# CTRL_MODULE_CORE register map
Vendor: Texas Instruments
Peripheral module from a debugger description file (folder DM50x).
Registers are 32-bit, access per field, reset 0x0 unless marked. A register's access mark holds for its fields unless they carry their own. Offsets are as the file gives them; lines under a group give offsets from that group; [hi:lo] are bit positions; {n}, {i} and the like mark numbered series; 'fields as' and 'values as' point back to an identical list; <NAME> marks a mode.

## CTRL_MODULE_CORE (part 1 of 5)
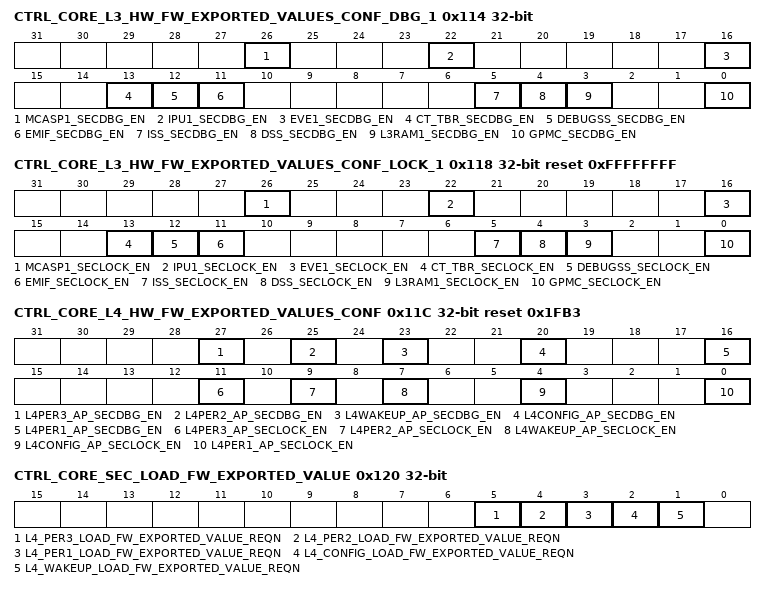
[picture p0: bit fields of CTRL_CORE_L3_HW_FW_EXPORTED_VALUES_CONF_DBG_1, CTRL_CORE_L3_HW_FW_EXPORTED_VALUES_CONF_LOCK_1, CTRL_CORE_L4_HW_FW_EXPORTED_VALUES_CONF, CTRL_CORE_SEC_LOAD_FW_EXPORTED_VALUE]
0x114 CTRL_CORE_L3_HW_FW_EXPORTED_VALUES_CONF_DBG_1
  [26] MCASP1_SECDBG_EN rw — Using a combination of x_SECDBG_EN and corresponding x_SECLOCK_EN bit from registerCTRL_CORE_L3_HW_FW_EXPORTED_VALUES_CONF_LOCK_1, different values can be exported to the corresponding L3 firewall. For more information, see , in .
  [22] IPU1_SECDBG_EN rw — Using a combination of x_SECDBG_EN and corresponding x_SECLOCK_EN bit from registerCTRL_CORE_L3_HW_FW_EXPORTED_VALUES_CONF_LOCK_1, different values can be exported to the corresponding L3 firewall. For more information, see , in .
  [16] EVE1_SECDBG_EN rw — Using a combination of x_SECDBG_EN and corresponding x_SECLOCK_EN bit from registerCTRL_CORE_L3_HW_FW_EXPORTED_VALUES_CONF_LOCK_1, different values can be exported to the corresponding L3 firewall. For more information, see , in .
  [13] CT_TBR_SECDBG_EN rw — Using a combination of x_SECDBG_EN and corresponding x_SECLOCK_EN bit from registerCTRL_CORE_L3_HW_FW_EXPORTED_VALUES_CONF_LOCK_1, different values can be exported to the corresponding L3 firewall. For more information, see , in .
  [12] DEBUGSS_SECDBG_EN rw — Using a combination of x_SECDBG_EN and corresponding x_SECLOCK_EN bit from registerCTRL_CORE_L3_HW_FW_EXPORTED_VALUES_CONF_LOCK_1, different values can be exported to the corresponding L3 firewall. For more information, see , in .
  [11] EMIF_SECDBG_EN rw — Using a combination of x_SECDBG_EN and corresponding x_SECLOCK_EN bit from registerCTRL_CORE_L3_HW_FW_EXPORTED_VALUES_CONF_LOCK_1, different values can be exported to the corresponding L3 firewall. For more information, see , in .
  [5] ISS_SECDBG_EN rw — Using a combination of x_SECDBG_EN and corresponding x_SECLOCK_EN bit from registerCTRL_CORE_L3_HW_FW_EXPORTED_VALUES_CONF_LOCK_1, different values can be exported to the corresponding L3 firewall. For more information, see , in .
  [4] DSS_SECDBG_EN rw — Using a combination of x_SECDBG_EN and corresponding x_SECLOCK_EN bit from registerCTRL_CORE_L3_HW_FW_EXPORTED_VALUES_CONF_LOCK_1, different values can be exported to the corresponding L3 firewall. For more information, see , in .
  [3] L3RAM1_SECDBG_EN rw — Using a combination of x_SECDBG_EN and corresponding x_SECLOCK_EN bit from registerCTRL_CORE_L3_HW_FW_EXPORTED_VALUES_CONF_LOCK_1, different values can be exported to the corresponding L3 firewall. For more information, see , in .
  [0] GPMC_SECDBG_EN rw — Using a combination of x_SECDBG_EN and corresponding x_SECLOCK_EN bit from registerCTRL_CORE_L3_HW_FW_EXPORTED_VALUES_CONF_LOCK_1, different values can be exported to the corresponding L3 firewall. For more information, see , in .
0x118 CTRL_CORE_L3_HW_FW_EXPORTED_VALUES_CONF_LOCK_1 reset 0xFFFFFFFF
  [26] MCASP1_SECLOCK_EN rw — Using a combination of x_SECLOCK_EN and corresponding x_SECDBG_EN bit from registerCTRL_CORE_L3_HW_FW_EXPORTED_VALUES_CONF_DBG_1, different values can be exported to the corresponding L3 firewall. For more information, see , in .
  [22] IPU1_SECLOCK_EN rw — Using a combination of x_SECLOCK_EN and corresponding x_SECDBG_EN bit from registerCTRL_CORE_L3_HW_FW_EXPORTED_VALUES_CONF_DBG_1, different values can be exported to the corresponding L3 firewall. For more information, see , in .
  [16] EVE1_SECLOCK_EN rw — Using a combination of x_SECLOCK_EN and corresponding x_SECDBG_EN bit from registerCTRL_CORE_L3_HW_FW_EXPORTED_VALUES_CONF_DBG_1, different values can be exported to the corresponding L3 firewall. For more information, see , in .
  [13] CT_TBR_SECLOCK_EN rw — Using a combination of x_SECLOCK_EN and corresponding x_SECDBG_EN bit from registerCTRL_CORE_L3_HW_FW_EXPORTED_VALUES_CONF_DBG_1, different values can be exported to the corresponding L3 firewall. For more information, see , in .
  [12] DEBUGSS_SECLOCK_EN rw — Using a combination of x_SECLOCK_EN and corresponding x_SECDBG_EN bit from registerCTRL_CORE_L3_HW_FW_EXPORTED_VALUES_CONF_DBG_1, different values can be exported to the corresponding L3 firewall. For more information, see , in .
  [11] EMIF_SECLOCK_EN rw — Using a combination of x_SECLOCK_EN and corresponding x_SECDBG_EN bit from registerCTRL_CORE_L3_HW_FW_EXPORTED_VALUES_CONF_DBG_1, different values can be exported to the corresponding L3 firewall. For more information, see , in .
  [5] ISS_SECLOCK_EN rw — Using a combination of x_SECLOCK_EN and corresponding x_SECDBG_EN bit from registerCTRL_CORE_L3_HW_FW_EXPORTED_VALUES_CONF_DBG_1, different values can be exported to the corresponding L3 firewall. For more information, see , in .
  [4] DSS_SECLOCK_EN rw — Using a combination of x_SECLOCK_EN and corresponding x_SECDBG_EN bit from registerCTRL_CORE_L3_HW_FW_EXPORTED_VALUES_CONF_DBG_1, different values can be exported to the corresponding L3 firewall. For more information, see , in .
  [3] L3RAM1_SECLOCK_EN rw — Using a combination of x_SECLOCK_EN and corresponding x_SECDBG_EN bit from registerCTRL_CORE_L3_HW_FW_EXPORTED_VALUES_CONF_DBG_1, different values can be exported to the corresponding L3 firewall. For more information, see , in .
  [0] GPMC_SECLOCK_EN rw — Using a combination of x_SECLOCK_EN and corresponding x_SECDBG_EN bit from registerCTRL_CORE_L3_HW_FW_EXPORTED_VALUES_CONF_DBG_1, different values can be exported to the corresponding L3 firewall. For more information, see , in .
0x11C CTRL_CORE_L4_HW_FW_EXPORTED_VALUES_CONF reset 0x1FB3
  [27] L4PER3_AP_SECDBG_EN rw — Using a combination of x_SECLOCK_EN and corresponding x_SECDBG_EN bit, different values can be exported to the corresponding L4 firewall. For more information, see table, in .
  [25] L4PER2_AP_SECDBG_EN rw — Using a combination of x_SECLOCK_EN and corresponding x_SECDBG_EN bit, different values can be exported to the corresponding L4 firewall. For more information, see table, in .
  [23] L4WAKEUP_AP_SECDBG_EN rw — Using a combination of x_SECLOCK_EN and corresponding x_SECDBG_EN bit, different values can be exported to the corresponding L4 firewall. For more information, see table, in .
  [20] L4CONFIG_AP_SECDBG_EN rw — Using a combination of x_SECLOCK_EN and corresponding x_SECDBG_EN bit, different values can be exported to the corresponding L4 firewall. For more information, see table, in .
  [16] L4PER1_AP_SECDBG_EN rw — Using a combination of x_SECLOCK_EN and corresponding x_SECDBG_EN bit, different values can be exported to the corresponding L4 firewall. For more information, see table, in .
  [11] L4PER3_AP_SECLOCK_EN rw — Using a combination of x_SECLOCK_EN and corresponding x_SECDBG_EN bit, different values can be exported to the corresponding L4 firewall. For more information, see table, in .
  [9] L4PER2_AP_SECLOCK_EN rw — Using a combination of x_SECLOCK_EN and corresponding x_SECDBG_EN bit, different values can be exported to the corresponding L4 firewall. For more information, see table, in .
  [7] L4WAKEUP_AP_SECLOCK_EN rw — Using a combination of x_SECLOCK_EN and corresponding x_SECDBG_EN bit, different values can be exported to the corresponding L4 firewall. For more information, see table, in .
  [4] L4CONFIG_AP_SECLOCK_EN rw — Using a combination of x_SECLOCK_EN and corresponding x_SECDBG_EN bit, different values can be exported to the corresponding L4 firewall. For more information, see table, in .
  [0] L4PER1_AP_SECLOCK_EN rw — Using a combination of x_SECLOCK_EN and corresponding x_SECDBG_EN bit, different values can be exported to the corresponding L4 firewall. For more information, see table, in .
0x120 CTRL_CORE_SEC_LOAD_FW_EXPORTED_VALUE
  [all] fields
    0=REQUESTED (LOAD FW exported values currently requested); 1=LOADED (FW exported values are LOADED)
  [5] L4_PER3_LOAD_FW_EXPORTED_VALUE_REQN rw — LOAD FW exported values.
  [4] L4_PER2_LOAD_FW_EXPORTED_VALUE_REQN rw — LOAD FW exported values.
  [3] L4_PER1_LOAD_FW_EXPORTED_VALUE_REQN rw — LOAD FW exported values.
  [2] L4_CONFIG_LOAD_FW_EXPORTED_VALUE_REQN rw — LOAD FW exported values.
  [1] L4_WAKEUP_LOAD_FW_EXPORTED_VALUE_REQN rw — LOAD FW exported values.
0x134 CTRL_CORE_STATUS ro reset 0xC0 — Control Module Status Register
  [8:6] DEVICE_TYPE — Device type captured at reset time. Read 0x3 = General Purpose (GP)
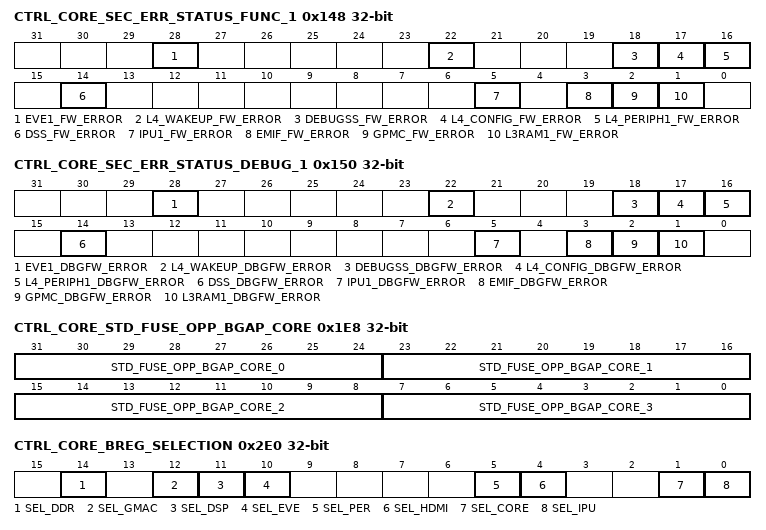
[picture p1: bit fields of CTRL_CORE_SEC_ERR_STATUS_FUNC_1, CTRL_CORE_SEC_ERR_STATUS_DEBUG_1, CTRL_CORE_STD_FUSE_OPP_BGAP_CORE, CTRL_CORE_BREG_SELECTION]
0x148 CTRL_CORE_SEC_ERR_STATUS_FUNC_1 access not given — Firewall Error Status functional Register 1
  [28] EVE1_FW_ERROR — EVE1 firewall 0x0 = No error from firewall 0x1 = Error from firewall (access RW W1toClr)
  [22] L4_WAKEUP_FW_ERROR — L4 wakeup firewall 0x0 = No error from firewall 0x1 = Error from firewall (access RW W1toClr)
  [18] DEBUGSS_FW_ERROR — DebugSS firewall 0x0 = No error from firewall 0x1 = Error from firewall (access RW W1toClr)
  [17] L4_CONFIG_FW_ERROR — L4 config firewall 0x0 = No error from firewall 0x1 = Error from firewall (access RW W1toClr)
  [16] L4_PERIPH1_FW_ERROR — L4 periph1 firewall 0x0 = No error from firewall 0x1 = Error from firewall (access RW W1toClr)
  [14] DSS_FW_ERROR — DSS firewall 0x0 = No error from firewall 0x1 = Error from firewall (access RW W1toClr)
  [5] IPU1_FW_ERROR — IPU1 firewall 0x0 = No error from firewall 0x1 = Error from firewall (access RW W1toClr)
  [3] EMIF_FW_ERROR — EMIF firewall 0x0 = No error from firewall 0x1 = Error from firewall (access RW W1toClr)
  [2] GPMC_FW_ERROR — GPMC firewall 0x0 = No error from firewall 0x1 = Error from firewall (access RW W1toClr)
  [1] L3RAM1_FW_ERROR — L3RAM1 firewall 0x0 = No error from firewall 0x1 = Error from firewall (access RW W1toClr)
0x150 CTRL_CORE_SEC_ERR_STATUS_DEBUG_1 access not given — Firewall Error Status Debug Register 1
  [28] EVE1_DBGFW_ERROR — EVE1 firewall 0x0 = No error from firewall 0x1 = Error from firewall (access RW W1toClr)
  [22] L4_WAKEUP_DBGFW_ERROR — L4 wakeup firewall 0x0 = No error from firewall 0x1 = Error from firewall (access RW W1toClr)
  [18] DEBUGSS_DBGFW_ERROR — DebugSS firewall 0x0 = No error from firewall 0x1 = Error from firewall (access RW W1toClr)
  [17] L4_CONFIG_DBGFW_ERROR — L4 config firewall 0x0 = No error from firewall 0x1 = Error from firewall (access RW W1toClr)
  [16] L4_PERIPH1_DBGFW_ERROR — L4 periph1 firewall 0x0 = No error from firewall 0x1 = Error from firewall (access RW W1toClr)
  [14] DSS_DBGFW_ERROR — DSS debug firewall 0x0 = No error from firewall 0x1 = Error from firewall (access RW W1toClr)
  [5] IPU1_DBGFW_ERROR — IPU1 debug firewall 0x0 = No error from firewall 0x1 = Error from firewall (access RW W1toClr)
  [3] EMIF_DBGFW_ERROR — EMIF debug firewall 0x0 = No error from firewall 0x1 = Error from firewall (access RW W1toClr)
  [2] GPMC_DBGFW_ERROR — GPMC debug firewall 0x0 = No error from firewall 0x1 = Error from firewall (access RW W1toClr)
  [1] L3RAM1_DBGFW_ERROR — L3RAM1 debug firewall 0x0 = No error from firewall 0x1 = Error from firewall (access RW W1toClr)
{0x1CC+4i} CTRL_CORE_STD_FUSE_OPP_VDD_CORE_{i} ro (i=0..4) — Standard Fuse OPP VDD_CORE [{32i+31}:{32i}]. Register shows part of the chip eFuse configuration on the OCP interface. Reading at the address of one of these registers provides a direct view into a part of the eFuse chain.
  [31:0] STD_FUSE_OPP_VDD_CORE_{i}
0x1E8 CTRL_CORE_STD_FUSE_OPP_BGAP_CORE ro reset not defined — Trim values for CORE associated temperature sensor and bandgap. Contains TI Internal information, not intended for application use.
  [31-8n:24-8n] STD_FUSE_OPP_BGAP_CORE_{n} (n=0..3) — Trim values for CORE associated temperature sensor and bandgap. Contains TI Internal information, not intended for application use.
{0x220+4i} CTRL_CORE_STD_FUSE_MPK_{i} ro (i=0..7) — Standard Fuse keys. Root_public_key_hash [{32i+31}:{32i}]. Register shows part of the chip eFuse configuration on the OCP interface. Reading at the address of one of these registers provides a direct view into a part of the eFuse chain.
  [31:0] STD_FUSE_MPK_{i}
0x2BC CTRL_CORE_CUST_FUSE_SWRV_0 ro — Customer Fuse keys. Software Version Control [031:000] (16 bits upper Redundant field) [FIELD OVERFLOW]. Register shows part of the chip eFuse configuration on the OCP interface. Reading at the address of one of these registers provides a direct view into a part of the eFuse chain.
  [31:0] CUST_FUSE_SWRV_0
0x2C0 CTRL_CORE_CUST_FUSE_SWRV_1 ro — Customer Fuse keys. Software Version Control [063:032] (16 bits upper Redundant field) [FIELD F]. Register shows part of the chip eFuse configuration on the OCP interface. Reading at the address of one of these registers provides a direct view into a part of the eFuse chain.
  [31:0] CUST_FUSE_SWRV_1
0x2C4 CTRL_CORE_CUST_FUSE_SWRV_2 ro — Customer Fuse keys. Software Version Control [095:064] (16 bits upper Redundant field) [FIELD E]. Register shows part of the chip eFuse configuration on the OCP interface. Reading at the address of one of these registers provides a direct view into a part of the eFuse chain.
  [31:0] CUST_FUSE_SWRV_2
0x2C8 CTRL_CORE_CUST_FUSE_SWRV_3 ro — Customer Fuse keys. Software Version Control [127:096] (16 bits upper Redundant field) [FIELD D]. Register shows part of the chip eFuse configuration on the OCP interface. Reading at the address of one of these registers provides a direct view into a part of the eFuse chain.
  [31:0] CUST_FUSE_SWRV_3
0x2CC CTRL_CORE_CUST_FUSE_SWRV_4 ro — Customer Fuse keys. Software Version Control [159:127] (16 bits upper Redundant field) [FIELD C]. Register shows part of the chip eFuse configuration on the OCP interface. Reading at the address of one of these registers provides a direct view into a part of the eFuse chain.
  [31:0] CUST_FUSE_SWRV_4
0x2D0 CTRL_CORE_CUST_FUSE_SWRV_5 ro — Customer Fuse keys. Software Version Control [191:160] (16 bits upper Redundant field) [FIELD B]. Register shows part of the chip eFuse configuration on the OCP interface. Reading at the address of one of these registers provides a direct view into a part of the eFuse chain.
  [31:0] CUST_FUSE_SWRV_5
0x2D4 CTRL_CORE_CUST_FUSE_SWRV_6 ro — Customer Fuse keys. Software Version Control [223:192] (16 bits upper Redundant field) [FIELD A]. Register shows part of the chip eFuse configuration on the OCP interface. Reading at the address of one of these registers provides a direct view into a part of the eFuse chain.
  [31:0] CUST_FUSE_SWRV_6
0x2E0 CTRL_CORE_BREG_SELECTION — DPLL selection
  [14] SEL_DDR rw — Selection ddr 0x0 = no dpll selected 0x1 = rdpll selected
  [12] SEL_GMAC rw — Selection gmac 0x0 = no dpll selected 0x1 = rdpll selected
  [11] SEL_DSP rw — Selection dsp 0x0 = no dpll selected 0x1 = rdpll selected
  [10] SEL_EVE rw — Selection eve 0x0 = no dpll selected 0x1 = rdpll selected
  [5] SEL_PER rw — Selection per 0x0 = no dpll selected 0x1 = rdpll selected
  [4] SEL_HDMI rw — Selection hdmi 0x0 = no dpll selected 0x1 = rdpll selected
  [1] SEL_CORE rw — Selection core 0x0 = no dpll selected 0x1 = rdpll selected
  [0] SEL_IPU rw — Selection ipu 0x0 = no dpll selected 0x1 = rdpll selected
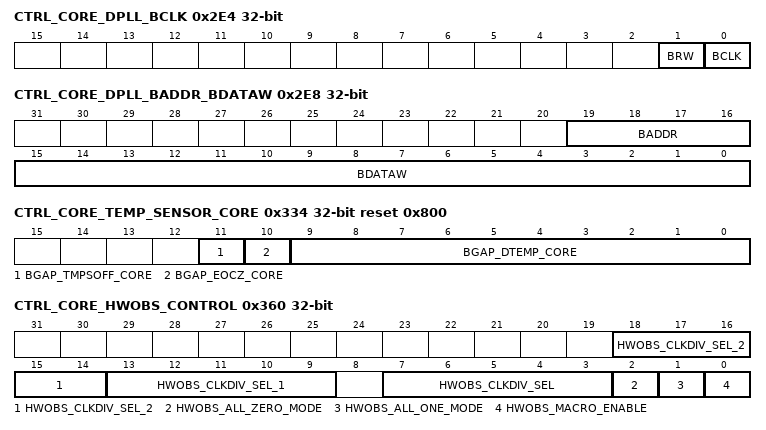
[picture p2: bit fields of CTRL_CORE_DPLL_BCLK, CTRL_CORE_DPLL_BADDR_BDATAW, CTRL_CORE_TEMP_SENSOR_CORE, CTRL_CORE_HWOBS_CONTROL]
0x2E4 CTRL_CORE_DPLL_BCLK — DPPL obs
  [1] BRW rw — Reset 0x0 = no reset 0x1 = reset
  [0] BCLK rw — clock
0x2E8 CTRL_CORE_DPLL_BADDR_BDATAW — DPLL addr and dataw
  [19:16] BADDR rw, [15:0] BDATAW rw
0x2EC CTRL_CORE_DPLL_BDATAR ro — DPLL datar
  [15:0] BDATAR — datar
0x334 CTRL_CORE_TEMP_SENSOR_CORE ro reset 0x800 — Control VBGAPTS temperature sensor and thermal comparator shutdown register
  [11] BGAP_TMPSOFF_CORE — This bit indicates the temperature sensor state.
  [10] BGAP_EOCZ_CORE — ADC End of Conversion. Active low, when BGAP_DTEMP_CORE is valid.
  [9:0] BGAP_DTEMP_CORE — Temperature data from the ADC. Valid if EOCZ is low.
0x358 CTRL_CORE_CORTEX_M4_MMUADDRTRANSLTR — Cortex M4 register
  [19:0] CORTEX_M4_MMUADDRTRANSLTR rw — Used to save the mmu address boot
0x35C CTRL_CORE_CORTEX_M4_MMUADDRLOGICTR
  [19:0] CORTEX_M4_MMUADDRLOGICTR rw
0x360 CTRL_CORE_HWOBS_CONTROL — HW observability control. This register enables or disables HW observability outputs (to save power primarily)
  [18:14] HWOBS_CLKDIV_SEL_2 rw — Clock divider selection for obs2 line. 0x1 = output is not divided 0x2 = output is divided by 2 0x4 = output is divided by 4 0x8 = output is divided by 8 0x10 = output is divided by 16
  [13:9] HWOBS_CLKDIV_SEL_1 rw — Clock divider selection for obs1 line. 0x1 = output is not divided 0x2 = output is divided by 2 0x4 = output is divided by 4 0x8 = output is divided by 8 0x10 = output is divided by 16
  [7:3] HWOBS_CLKDIV_SEL rw — Clock divider selection for obs0 line. 0x1 = output is not divided 0x2 = output is divided by 2 0x4 = output is divided by 4 0x8 = output is divided by 8 0x10 = output is divided by 16
  [2] HWOBS_ALL_ZERO_MODE rw — Used to gate observable signals. When set all outputs are set to zero (can be used to check the path from HW observability to external pads). 0x0 = hw observability ports are not gated 0x1 = hw observability ports are all set to 0
  [1] HWOBS_ALL_ONE_MODE rw — Used to gate observable signals. When set all outputs are set to one (can be used to check the path from HW observability to external pads). 0x0 = hw observability ports are not gated 0x1 = hw observability ports are all set to 1
  [0] HWOBS_MACRO_ENABLE rw — Used to gate observable signals coming from macros using the 32-bit HWOBS bus definition. When deasserted all outputs of the HWOBS busdef are set to zero. 0x0 = hw observability ports from macros are gated and set to zero 0x1 = hw observability ports from macros are not gated
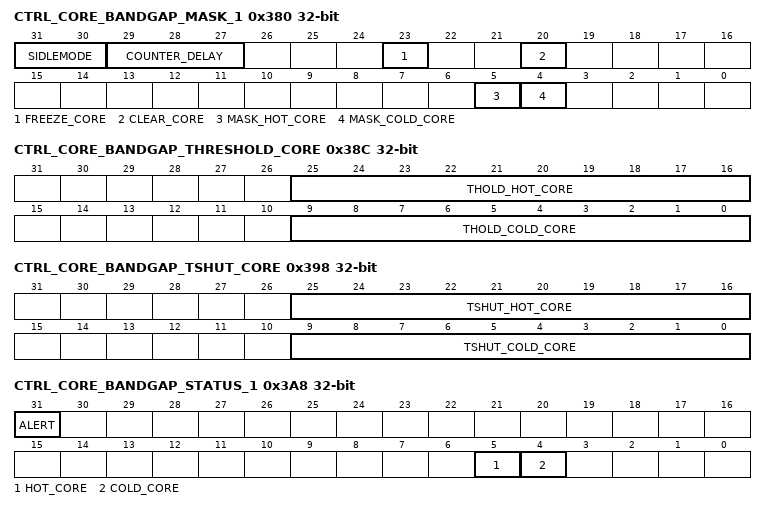
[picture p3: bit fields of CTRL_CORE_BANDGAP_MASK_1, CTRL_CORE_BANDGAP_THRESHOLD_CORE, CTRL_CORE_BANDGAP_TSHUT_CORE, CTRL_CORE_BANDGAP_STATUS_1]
0x380 CTRL_CORE_BANDGAP_MASK_1 — bgap_mask
  [31:30] SIDLEMODE rw — sidlemode for bandgap 0x0 = No Idle 0x1 = Force Idle 0x2 = Smart Idle 0x3 = Reserved
  [29:27] COUNTER_DELAY rw — Counter delay 0x0 = Imediat 0x1 = Delay of 1ms 0x2 = Delay of 10ms 0x3 = Delay of 100ms 0x4 = Delay of 250ms 0x5 = Delay of 500ms
  [23] FREEZE_CORE rw — Freeze the FIFO CORE 0x0 = No operation 0x1 = Freeze the FIFO
  [20] CLEAR_CORE rw — Reset the FIFO CORE 0x0 = No operation 0x1 = Reset the FIFO
  [5] MASK_HOT_CORE rw — Mask for hot event CORE 0x0 = hot event is masked 0x1 = hot event is not masked
  [4] MASK_COLD_CORE rw — Mask for cold event CORE 0x0 = cold event is masked 0x1 = cold event is not masked
0x38C CTRL_CORE_BANDGAP_THRESHOLD_CORE — BGAP THRESHOLD CORE
  [25:16] THOLD_HOT_CORE rw — Value for the high temperature threshold. The values for loading this bit field are listed in.
  [9:0] THOLD_COLD_CORE rw — Value for the low temperature threshold. The values for loading this bit field are listed in.
0x398 CTRL_CORE_BANDGAP_TSHUT_CORE ro — BGAP TSHUT THRESHOLD CORE
  [25:16] TSHUT_HOT_CORE — tshut value hot
  [9:0] TSHUT_COLD_CORE — tshut value cold
0x3A8 CTRL_CORE_BANDGAP_STATUS_1 ro — BGAP STATUS
  [31] ALERT — Alert temperature when '1'
  [5] HOT_CORE — Event for hot temperature mpu bandgap when '1' 0x0 = event not detected 0x1 = event detected
  [4] COLD_CORE — Event for cold temperature mpu bandgap when '1' 0x0 = event not detected 0x1 = event detected
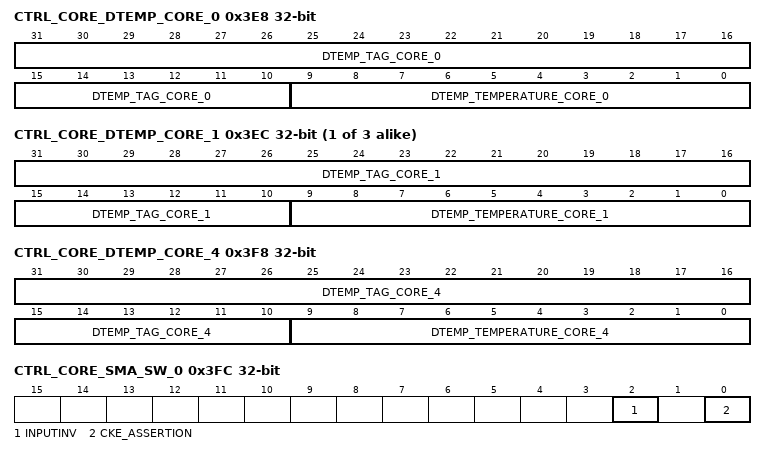
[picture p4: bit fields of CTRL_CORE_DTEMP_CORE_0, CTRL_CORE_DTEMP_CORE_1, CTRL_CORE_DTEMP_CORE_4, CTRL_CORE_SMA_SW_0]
0x3E8 CTRL_CORE_DTEMP_CORE_0 ro — TAGGED TEMPERATURE CORE DOMAIN. Most recent sample.
  [31:10] DTEMP_TAG_CORE_0 — tag. Indicate number of times in the bgap state machine.
  [9:0] DTEMP_TEMPERATURE_CORE_0 — temperature
{0x3E8+4i} CTRL_CORE_DTEMP_CORE_{i} ro (i=1..3) — TAGGED TEMPERATURE CORE DOMAIN
  [31:10] DTEMP_TAG_CORE_{i} — tag. Indicate number of times in the bgap state machine.
  [9:0] DTEMP_TEMPERATURE_CORE_{i} — temperature
0x3F8 CTRL_CORE_DTEMP_CORE_4 ro — TAGGED TEMPERATURE CORE DOMAIN. Oldest sample.
  [31:10] DTEMP_TAG_CORE_4 — tag. Indicate number of times in the bgap state machine.
  [9:0] DTEMP_TEMPERATURE_CORE_4 — temperature
0x3FC CTRL_CORE_SMA_SW_0 — Inversion control for SD_DAC input data – DIN[9:0].
  [2] INPUTINV rw — Inversion control for SD_DAC input data – DIN[9:0]. Allows polarity alignment with VENC data. 0x0: This value should be used for inverted video input data 0x1: This value should be used for non-inverted video input data
  [0] CKE_ASSERTION rw — Forces the EMIF CKE pad to tri-state. 0x0: The CKE pad is not in tri-state and can be controlled by EMIF 0x1: The CKE pad is in tri-state
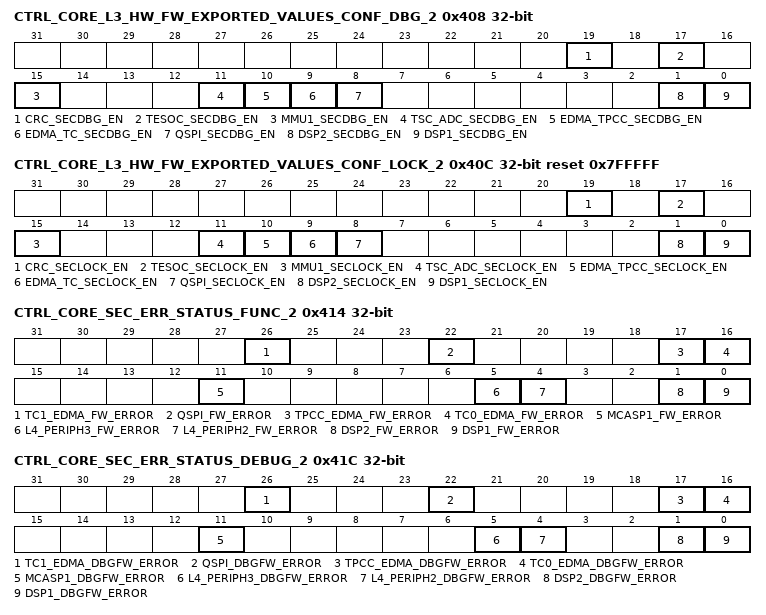
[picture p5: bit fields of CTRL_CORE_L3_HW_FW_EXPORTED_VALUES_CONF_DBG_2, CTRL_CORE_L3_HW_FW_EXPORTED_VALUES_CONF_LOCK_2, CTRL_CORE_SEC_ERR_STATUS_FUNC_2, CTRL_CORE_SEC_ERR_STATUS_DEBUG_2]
0x408 CTRL_CORE_L3_HW_FW_EXPORTED_VALUES_CONF_DBG_2
  [19] CRC_SECDBG_EN rw — Using a combination of x_SECDBG_EN and corresponding x_SECLOCK_EN bit from registerCTRL_CORE_L3_HW_FW_EXPORTED_VALUES_CONF_LOCK_2, different values can be exported to the corresponding L3 firewall. For more information, see , in .
  [17] TESOC_SECDBG_EN rw — Using a combination of x_SECDBG_EN and corresponding x_SECLOCK_EN bit from registerCTRL_CORE_L3_HW_FW_EXPORTED_VALUES_CONF_LOCK_2, different values can be exported to the corresponding L3 firewall. For more information, see , in .
  [15] MMU1_SECDBG_EN rw — Using a combination of x_SECDBG_EN and corresponding x_SECLOCK_EN bit from registerCTRL_CORE_L3_HW_FW_EXPORTED_VALUES_CONF_LOCK_2, different values can be exported to the corresponding L3 firewall. For more information, see , in .
  [11] TSC_ADC_SECDBG_EN rw — Using a combination of x_SECDBG_EN and corresponding x_SECLOCK_EN bit from registerCTRL_CORE_L3_HW_FW_EXPORTED_VALUES_CONF_LOCK_2, different values can be exported to the corresponding L3 firewall. For more information, see , in .
  [10] EDMA_TPCC_SECDBG_EN rw — Using a combination of x_SECDBG_EN and corresponding x_SECLOCK_EN bit from registerCTRL_CORE_L3_HW_FW_EXPORTED_VALUES_CONF_LOCK_2, different values can be exported to the corresponding L3 firewall. For more information, see , in .
  [9] EDMA_TC_SECDBG_EN rw — Using a combination of x_SECDBG_EN and corresponding x_SECLOCK_EN bit from registerCTRL_CORE_L3_HW_FW_EXPORTED_VALUES_CONF_LOCK_2, different values can be exported to the corresponding L3 firewall. For more information, see , in .
  [8] QSPI_SECDBG_EN rw — Using a combination of x_SECDBG_EN and corresponding x_SECLOCK_EN bit from registerCTRL_CORE_L3_HW_FW_EXPORTED_VALUES_CONF_LOCK_2, different values can be exported to the corresponding L3 firewall. For more information, see , in .
  [1] DSP2_SECDBG_EN rw — Using a combination of x_SECDBG_EN and corresponding x_SECLOCK_EN bit from registerCTRL_CORE_L3_HW_FW_EXPORTED_VALUES_CONF_LOCK_2, different values can be exported to the corresponding L3 firewall. For more information, see , in .
  [0] DSP1_SECDBG_EN rw — Using a combination of x_SECDBG_EN and corresponding x_SECLOCK_EN bit from registerCTRL_CORE_L3_HW_FW_EXPORTED_VALUES_CONF_LOCK_2, different values can be exported to the corresponding L3 firewall. For more information, see , in .
0x40C CTRL_CORE_L3_HW_FW_EXPORTED_VALUES_CONF_LOCK_2 reset 0x7FFFFF
  [19] CRC_SECLOCK_EN rw — Using a combination of x_SECLOCK_EN and corresponding x_SECDBG_EN bit from registerCTRL_CORE_L3_HW_FW_EXPORTED_VALUES_CONF_DBG_2, different values can be exported to the corresponding L3 firewall. For more information, see , in .
  [17] TESOC_SECLOCK_EN rw — Using a combination of x_SECLOCK_EN and corresponding x_SECDBG_EN bit from registerCTRL_CORE_L3_HW_FW_EXPORTED_VALUES_CONF_DBG_2, different values can be exported to the corresponding L3 firewall. For more information, see , in .
  [15] MMU1_SECLOCK_EN rw — Using a combination of x_SECLOCK_EN and corresponding x_SECDBG_EN bit from registerCTRL_CORE_L3_HW_FW_EXPORTED_VALUES_CONF_DBG_2, different values can be exported to the corresponding L3 firewall. For more information, see , in .
  [11] TSC_ADC_SECLOCK_EN rw — Using a combination of x_SECLOCK_EN and corresponding x_SECDBG_EN bit from registerCTRL_CORE_L3_HW_FW_EXPORTED_VALUES_CONF_DBG_2, different values can be exported to the corresponding L3 firewall. For more information, see , in .
  [10] EDMA_TPCC_SECLOCK_EN rw — Using a combination of x_SECLOCK_EN and corresponding x_SECDBG_EN bit from registerCTRL_CORE_L3_HW_FW_EXPORTED_VALUES_CONF_DBG_2, different values can be exported to the corresponding L3 firewall. For more information, see , in .
  [9] EDMA_TC_SECLOCK_EN rw — Using a combination of x_SECLOCK_EN and corresponding x_SECDBG_EN bit from registerCTRL_CORE_L3_HW_FW_EXPORTED_VALUES_CONF_DBG_2, different values can be exported to the corresponding L3 firewall. For more information, see , in .
  [8] QSPI_SECLOCK_EN rw — Using a combination of x_SECLOCK_EN and corresponding x_SECDBG_EN bit from registerCTRL_CORE_L3_HW_FW_EXPORTED_VALUES_CONF_DBG_2, different values can be exported to the corresponding L3 firewall. For more information, see , in .
  [1] DSP2_SECLOCK_EN rw — Using a combination of x_SECLOCK_EN and corresponding x_SECDBG_EN bit from registerCTRL_CORE_L3_HW_FW_EXPORTED_VALUES_CONF_DBG_2, different values can be exported to the corresponding L3 firewall. For more information, see , in .
  [0] DSP1_SECLOCK_EN rw — Using a combination of x_SECLOCK_EN and corresponding x_SECDBG_EN bit from registerCTRL_CORE_L3_HW_FW_EXPORTED_VALUES_CONF_DBG_2, different values can be exported to the corresponding L3 firewall. For more information, see , in .
0x414 CTRL_CORE_SEC_ERR_STATUS_FUNC_2 access not given — Firewall Error Status functional Register 2
  [26] TC1_EDMA_FW_ERROR — EDMA TC1 firewall 0x0 = No error from firewall 0x1 = Error from firewall (access RW W1toClr)
  [22] QSPI_FW_ERROR — QSPI firewall 0x0 = No error from firewall 0x1 = Error from firewall (access RW W1toClr)
  [17] TPCC_EDMA_FW_ERROR — EDMA TPCC firewall 0x0 = No error from firewall 0x1 = Error from firewall (access RW W1toClr)
  [16] TC0_EDMA_FW_ERROR — EDMA TC0 firewall 0x0 = No error from firewall 0x1 = Error from firewall (access RW W1toClr)
  [11] MCASP1_FW_ERROR — McASP1 firewall 0x0 = No error from firewall 0x1 = Error from firewall (access RW W1toClr)
  [5] L4_PERIPH3_FW_ERROR — L4 periph3 init firewall 0x0 = No error from firewall 0x1 = Error from firewall (access RW W1toClr)
  [4] L4_PERIPH2_FW_ERROR — L4 periph2 init firewall 0x0 = No error from firewall 0x1 = Error from firewall (access RW W1toClr)
  [1] DSP2_FW_ERROR — DSP2 firewall 0x0 = No error from firewall 0x1 = Error from firewall (access RW W1toClr)
  [0] DSP1_FW_ERROR — DSP1 firewall 0x0 = No error from firewall 0x1 = Error from firewall (access RW W1toClr)
0x41C CTRL_CORE_SEC_ERR_STATUS_DEBUG_2 access not given — Firewall Error Status debug Register 2
  [26] TC1_EDMA_DBGFW_ERROR — EDMA TC1 debug firewall 0x0 = No error from firewall 0x1 = Error from firewall (access RW W1toClr)
  [22] QSPI_DBGFW_ERROR — QSPI debug firewall 0x0 = No error from firewall 0x1 = Error from firewall (access RW W1toClr)
  [17] TPCC_EDMA_DBGFW_ERROR — EDMA TPCC debug firewall 0x0 = No error from firewall 0x1 = Error from firewall (access RW W1toClr)
  [16] TC0_EDMA_DBGFW_ERROR — EDMA TC0 debug firewall 0x0 = No error from firewall 0x1 = Error from firewall (access RW W1toClr)
  [11] MCASP1_DBGFW_ERROR — McASP1 debug firewall 0x0 = No error from firewall 0x1 = Error from firewall (access RW W1toClr)
  [5] L4_PERIPH3_DBGFW_ERROR — L4 periph3 init firewall 0x0 = No error from firewall 0x1 = Error from firewall (access RW W1toClr)
  [4] L4_PERIPH2_DBGFW_ERROR — L4 periph2 init firewall 0x0 = No error from firewall 0x1 = Error from firewall (access RW W1toClr)
  [1] DSP2_DBGFW_ERROR — DSP2 firewall 0x0 = No error from firewall 0x1 = Error from firewall (access RW W1toClr)
  [0] DSP1_DBGFW_ERROR — DSP1 firewall 0x0 = No error from firewall 0x1 = Error from firewall (access RW W1toClr)
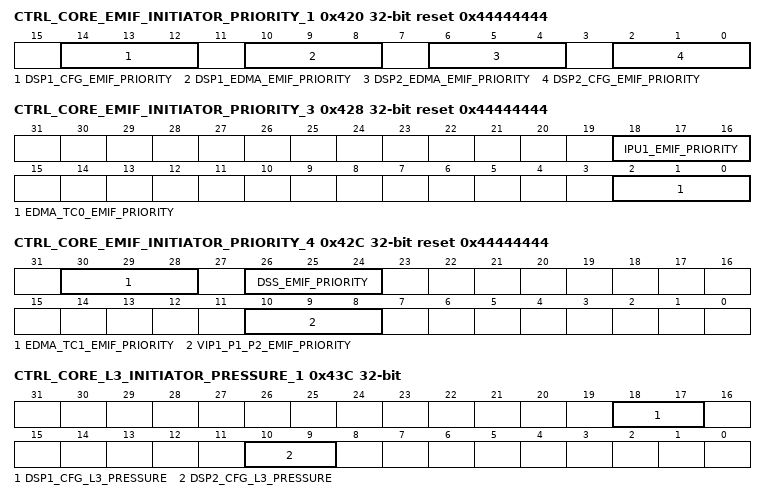
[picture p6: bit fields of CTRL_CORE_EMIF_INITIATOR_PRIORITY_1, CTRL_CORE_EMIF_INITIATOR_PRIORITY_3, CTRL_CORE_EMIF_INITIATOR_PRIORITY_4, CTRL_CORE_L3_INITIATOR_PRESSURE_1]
0x420 CTRL_CORE_EMIF_INITIATOR_PRIORITY_1 reset 0x44444444 — Register for priority settings for EMIF arbitration
  [14:12] DSP1_CFG_EMIF_PRIORITY rw — DSP1 CFG priority setting 0x0 = highest priority 0x7 = lowest priority
  [10:8] DSP1_EDMA_EMIF_PRIORITY rw — DSP1 EDMA priority setting 0x0 = highest priority 0x7 = lowest priority
  [6:4] DSP2_EDMA_EMIF_PRIORITY rw — DSP2 EDMA priority setting 0x0 = highest priority 0x7 = lowest priority
  [2:0] DSP2_CFG_EMIF_PRIORITY rw — DSP2 CFG priority setting 0x0 = highest priority 0x7 = lowest priority
0x424 CTRL_CORE_EMIF_INITIATOR_PRIORITY_2 reset 0x44044444 — Register for priority settings for EMIF arbitration
  [18:16] EVE1_TC0_EMIF_PRIORITY rw — EVE1 TC0 priority setting 0x0 = highest priority 0x7 = lowest priority
0x428 CTRL_CORE_EMIF_INITIATOR_PRIORITY_3 reset 0x44444444 — Register for priority settings for EMIF arbitration
  [18:16] IPU1_EMIF_PRIORITY rw — IPU1 priority setting 0x0 = highest prioroty 0x7 = lowest priority
  [2:0] EDMA_TC0_EMIF_PRIORITY rw — EDMA TC0 priority setting 0x0 = highest priority 0x7 = lowest priority
0x42C CTRL_CORE_EMIF_INITIATOR_PRIORITY_4 reset 0x44444444 — Register for priority settings for EMIF arbitration
  [30:28] EDMA_TC1_EMIF_PRIORITY rw — EDMA TC1 priority setting 0x0 = highest priority 0x7 = lowest priority
  [26:24] DSS_EMIF_PRIORITY rw — DSS priority setting 0x0 = highest priority 0x7 = lowest priority
  [10:8] VIP1_P1_P2_EMIF_PRIORITY rw — VIP1 priority setting 0x0 = highest priority 0x7 = lowest priority
0x430 CTRL_CORE_EMIF_INITIATOR_PRIORITY_5 reset 0x44444444 — Register for priority settings for EMIF arbitration
  [14:12] GMAC_SW_EMIF_PRIORITY rw — GMAC_SW priority setting 0x0 = highest priority 0x7 = lowest priority
0x434 CTRL_CORE_EMIF_INITIATOR_PRIORITY_6 reset 0x44444444 — Register for priority settings for EMIF arbitration
  [10:8] EVE1_TC1_EMIF_PRIORITY rw — EVE1 TC1 priority setting 0x0 = highest priority 0x7 = lowest priority
0x43C CTRL_CORE_L3_INITIATOR_PRESSURE_1 — Register for pressure settings for L3 arbitration
  [18:17] DSP1_CFG_L3_PRESSURE rw — DSP1 CFG pressure setting 0x0 = lowest 0x3 = highest
  [10:9] DSP2_CFG_L3_PRESSURE rw — DSP2 CFG pressure setting 0x0 = lowest 0x3 = highest
0x4E8 CTRL_CORE_CUST_FUSE_UID_0 ro — Customer Fuse keys. UID [031:000] (16 bits upper Redundant field) [FIELD OVERFLOW]. Register shows part of the chip eFuse configuration on the OCP interface. Reading at the address of one of these registers provides a direct view into a part of the eFuse chain.
  [31:0] CUST_FUSE_UID_0
0x4EC CTRL_CORE_CUST_FUSE_UID_1 ro — Customer Fuse keys. UID [063:032] (16 bits upper Redundant field) [FIELD F]. Register shows part of the chip eFuse configuration on the OCP interface. Reading at the address of one of these registers provides a direct view into a part of the eFuse chain.
  [31:0] CUST_FUSE_UID_1
0x4F0 CTRL_CORE_CUST_FUSE_UID_2 ro — Customer Fuse keys. UID [095:064] (16 bits upper Redundant field) [FIELD E]. Register shows part of the chip eFuse configuration on the OCP interface. Reading at the address of one of these registers provides a direct view into a part of the eFuse chain.
  [31:0] CUST_FUSE_UID_2
0x4F4 CTRL_CORE_CUST_FUSE_UID_3 ro — Customer Fuse keys. UID [127:096] (16 bits upper Redundant field) [FIELD D]. Register shows part of the chip eFuse configuration on the OCP interface. Reading at the address of one of these registers provides a direct view into a part of the eFuse chain.
  [31:0] CUST_FUSE_UID_3
0x4F8 CTRL_CORE_CUST_FUSE_UID_4 ro — Customer Fuse keys. UID [159:127] (16 bits upper Redundant field) [FIELD C]. Register shows part of the chip eFuse configuration on the OCP interface. Reading at the address of one of these registers provides a direct view into a part of the eFuse chain.
  [31:0] CUST_FUSE_UID_4
0x4FC CTRL_CORE_CUST_FUSE_UID_5 ro — Customer Fuse keys. UID [191:160] (16 bits upper Redundant field) [FIELD B]. Register shows part of the chip eFuse configuration on the OCP interface. Reading at the address of one of these registers provides a direct view into a part of the eFuse chain.
  [31:0] CUST_FUSE_UID_5
0x500 CTRL_CORE_CUST_FUSE_UID_6 ro — Customer Fuse keys. UID [223:192] (16 bits upper Redundant field) [FIELD A]. Register shows part of the chip eFuse configuration on the OCP interface. Reading at the address of one of these registers provides a direct view into a part of the eFuse chain.
  [31:0] CUST_FUSE_UID_6
0x514 CTRL_CORE_MAC_ID_SW_0 ro — Standard Fuse keys, MAC ID_1 [63:32].
  [23:0] STD_FUSE_MAC_ID_SW_0 — This bit field contains the last three octets (NIC specific) of the MAC address of the GMAC_SW port 0. Bits [23:16] contain the fourth octet of the MAC address. Bits [15:8] contain the fifth octet of the MAC address. Bits [7:0] contain the last (sixth) octet of the MAC address.
0x518 CTRL_CORE_MAC_ID_SW_1 ro — Standard Fuse keys, MAC ID_1 [31:0].
  [23:0] STD_FUSE_MAC_ID_SW_1 — This bit field contains the last three octets (the OUI) of the MAC address of the GMAC_SW port 0. Bits [23:16] contain the first octet of the MAC address. Bits [15:8] contain the second octet of the MAC address. Bits [7:0] contain the third octet of the MAC address.
0x51C CTRL_CORE_MAC_ID_SW_2 ro — Standard Fuse keys, MAC ID_2 [63:32].
  [23:0] STD_FUSE_MAC_ID_SW_2 — This bit field contains the last three octets (NIC specific) of the MAC address of the GMAC_SW port 1. Bits [23:16] contain the fourth octet of the MAC address. Bits [15:8] contain the fifth octet of the MAC address. Bits [7:0] contain the last (sixth) octet of the MAC address.
0x520 CTRL_CORE_MAC_ID_SW_3 ro — Standard Fuse keys, MAC ID_2 [31:0].
  [23:0] STD_FUSE_MAC_ID_SW_3 — This bit field contains the last three octets (the OUI) of the MAC address of the GMAC_SW port 1. Bits [23:16] contain the first octet of the MAC address. Bits [15:8] contain the second octet of the MAC address. Bits [7:0] contain the third octet of the MAC address.
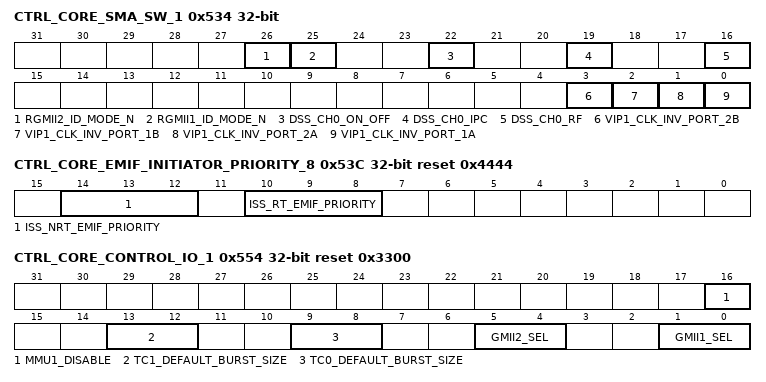
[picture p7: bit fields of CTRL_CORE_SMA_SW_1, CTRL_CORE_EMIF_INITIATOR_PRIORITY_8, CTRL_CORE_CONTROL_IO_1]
0x534 CTRL_CORE_SMA_SW_1 — OCP Spare Register
  [26] RGMII2_ID_MODE_N rw — Ethernet RGMII port 2 internal delay on transmit (SR2.0 Only) 0x0: Internal delay enabled 0x1: Internal delay disabled
  [25] RGMII1_ID_MODE_N rw — Ethernet RGMII port 1 internal delay on transmit (SR2.0 Only) 0x0: Internal delay enabled 0x1: Internal delay disabled
  [22] DSS_CH0_ON_OFF rw — DSS Channel 0 Pixel clock control On/Off 0x0: HSYNC and VSYNC are driven on opposite edges of pixel clock than pixel data 0x1: HSYNC and VSYNC are driven according to bit DSS_CH0_RF
  [19] DSS_CH0_IPC rw — DSS Channel 0 IPC control 0x0: Data is driven on the LCD data lines on the rising edge of the pixel clock 0x1: Data is driven on the LCD data lines on the falling edge of the pixel clock
  [16] DSS_CH0_RF rw — DSS Channel 0 Rise/Fall control 0x0: HSYNC and VSYNC are driven on falling edge of pixel clock (if bit DSS_CH0_ON_OFF set to 1) 0x1: HSYNC and VSYNC are driven on rising edge of pixel clock (if bit DSS_CH0_ON_OFF set to 1)
  [3] VIP1_CLK_INV_PORT_2B rw — VIP1 Slice 1 Clock inversion for Port B enable 0x0: Clock inversion is disabled 0x1: Clock inversion is enabled
  [2] VIP1_CLK_INV_PORT_1B rw — VIP1 Slice 0 Clock inversion for Port B enable 0x0: Clock inversion is disabled 0x1: Clock inversion is enabled
  [1] VIP1_CLK_INV_PORT_2A rw — VIP1 Slice 1 Clock inversion for Port A enable 0x0: Clock inversion is disabled 0x1: Clock inversion is enabled
  [0] VIP1_CLK_INV_PORT_1A rw — VIP1 Slice 0 Clock inversion for Port A enable 0x0: Clock inversion is disabled 0x1: Clock inversion is enabled
0x53C CTRL_CORE_EMIF_INITIATOR_PRIORITY_8 reset 0x4444 — Register for priority settings for EMIF arbitration
  [14:12] ISS_NRT_EMIF_PRIORITY rw — ISS NRT ports priority setting.
    0=highest priority; 7=lowest priority
  [10:8] ISS_RT_EMIF_PRIORITY rw — ISS RT port priority setting.
    0=highest priority; 7=lowest priority
0x540 CTRL_CORE_MMR_LOCK_1 rw reset 0x1A1C8144 — Register to lock memory regions from 0x0000 0100 to 0x0000 079F and from 0x0000 1A00 to 0x0000 1FFF
  [31:0] MMR_LOCK_1 — Lock value for regions 0x0000 0100 to 0x0000 079F and 0x0000 1A00 to 0x0000 1FFF 0x1A1C8144 = lock value 0x2FF1AC2B = unlock value
0x544 CTRL_CORE_MMR_LOCK_2 rw reset 0xFDF45530 — Register to lock memory region starting at address offset 0x0000 07A0 and ending at address offset 0x0000 0D9F
  [31:0] MMR_LOCK_2 — Lock value for region 0x0000 07A0 to 0x0000 0D9F 0xFDF45530 = lock value 0xF757FDC0 = unlock value
0x548 CTRL_CORE_MMR_LOCK_3 rw reset 0x1AE6E320 — Register to lock memory region starting at address offset 0x0000 0DA0 and ending at address offset 0x0000 0FFF
  [31:0] MMR_LOCK_3 — Lock value for region 0x0000 0DA0 to 0x0000 0FFF 0x1AE6E320 = lock value 0xE2BC3A6D = unlock value
0x54C CTRL_CORE_MMR_LOCK_4 rw reset 0x2FFA927C — Register to lock memory region starting at address offset 0x0000 1000 and ending at address offset 0x0000 13FF
  [31:0] MMR_LOCK_4 — Lock value for region 0x0000 1000 to 0x0000 13FF 0x2FFA927C = lock value 0x1EBF131D = unlock value
0x550 CTRL_CORE_MMR_LOCK_5 rw reset 0x143F832C — Register to lock memory region starting at address offset 0x0000 1400 and ending at address offset 0x0000 19FF
  [31:0] MMR_LOCK_5 — Lock value for region 0x0000 1400 to 0x0000 19FF 0x143F832C = lock value 0x6F361E05 = unlock value
0x554 CTRL_CORE_CONTROL_IO_1 reset 0x3300 — Register to configure some IP level signals
  [16] MMU1_DISABLE rw — MMU1 DISABLE setting
  [13:12] TC1_DEFAULT_BURST_SIZE rw — EDMA TC1 DEFAULT BURST SIZE setting
  [9:8] TC0_DEFAULT_BURST_SIZE rw — EDMA TC0 DEFAULT BURST SIZE setting
  [5:4] GMII2_SEL rw — GMII2 selection setting 0x0: GMII/MII 0x1: RMII 0x2: RGMII 0x3: Reserved
  [1:0] GMII1_SEL rw — GMII1 selection setting 0x0: GMII/MII 0x1: RMII 0x2: RGMII 0x3: Reserved
